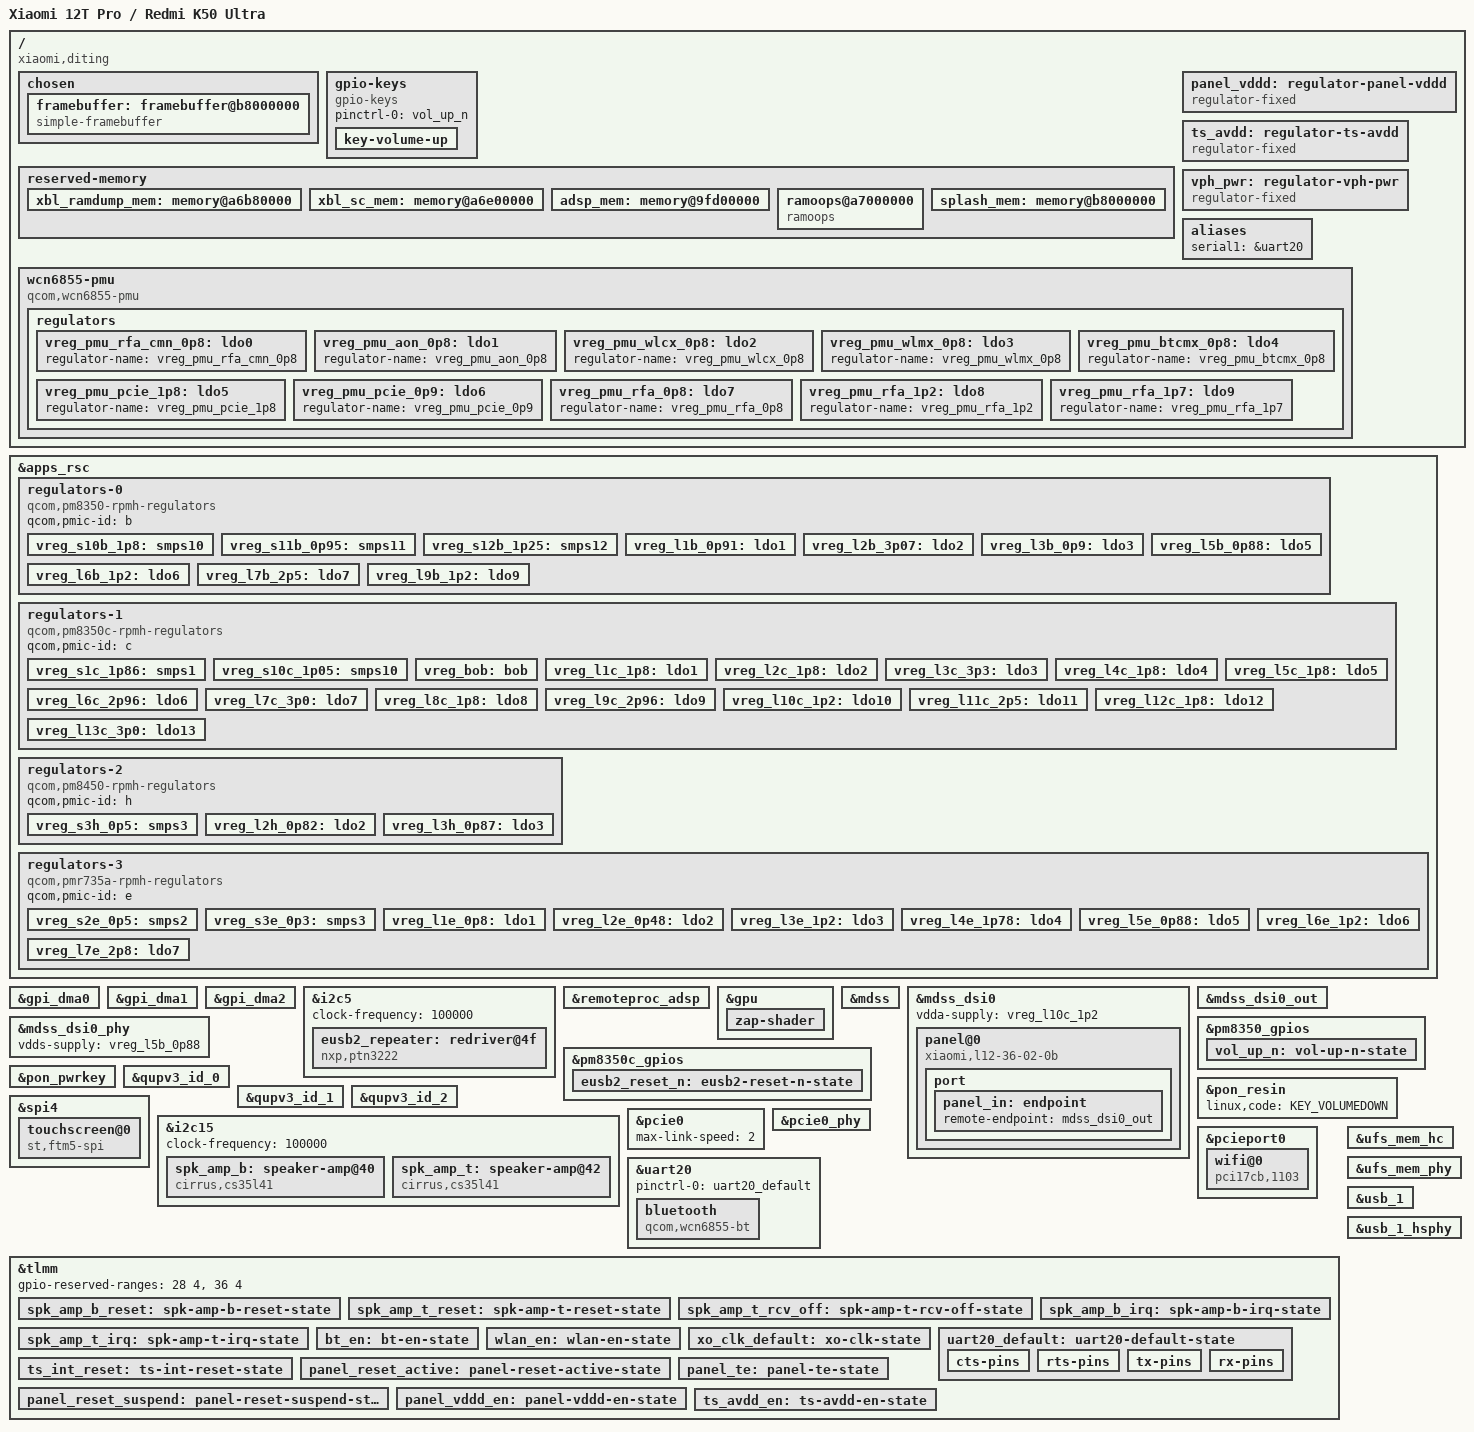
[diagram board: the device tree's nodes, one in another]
// SPDX-License-Identifier: BSD-3-Clause
/*
 * Xiaomi 12T Pro / Redmi K50 Ultra (diting)
 *
 * Local bring-up device tree. Board values were taken from the vendor
 * device tree of a 22081212UG (EEA, HyperOS OS3.0.5.0.VLFEUXM) unit, read
 * from /sys/firmware/fdt, and cross-checked with the sm8450-mainline
 * community sm8475-xiaomi-diting.dts by Jens Reidel.
 */

/dts-v1/;

#include <dt-bindings/gpio/gpio.h>
#include <dt-bindings/input/input.h>
#include <dt-bindings/interrupt-controller/irq.h>
#include <dt-bindings/pinctrl/qcom,pmic-gpio.h>
#include <dt-bindings/regulator/qcom,rpmh-regulator.h>

#include "sm8475.dtsi"
#include "pm8350.dtsi"
#include "pm8350b.dtsi"
#include "pm8350c.dtsi"
#include "pm8450.dtsi"
#include "pmk8350.dtsi"
#include "pmr735a.dtsi"

/*
 * The SM8450 reference carveouts below do not match this board: the vendor
 * DT places xbl_ramdump/xbl_sc and the ADSP elsewhere, and the generic
 * rmtfs location overlaps the Diting ADSP region. rmtfs is allocated
 * dynamically by the vendor kernel; it is left out until the modem is
 * brought up.
 */
/delete-node/ &adsp_mem;
/delete-node/ &rmtfs_mem;
/delete-node/ &xbl_ramdump_mem;
/delete-node/ &xbl_sc_mem;

/ {
	model = "Xiaomi 12T Pro / Redmi K50 Ultra";
	compatible = "xiaomi,diting", "qcom,sm8475";
	chassis-type = "handset";

	/*
	 * qcom,msm-id/qcom,board-id (needed by ABL to select a DTB from
	 * vendor_boot) are deprecated for this SoC generation and are added
	 * to a copy of the DTB by the boot image tooling instead.
	 */

	chosen {
		#address-cells = <2>;
		#size-cells = <2>;
		ranges;

		/* Continuous-splash buffer set up by ABL, 1220x2712 */
		framebuffer: framebuffer@b8000000 {
			compatible = "simple-framebuffer";
			reg = <0x0 0xb8000000 0x0 0x2b00000>;
			width = <1220>;
			height = <2712>;
			stride = <(1220 * 4)>;
			format = "a8r8g8b8";

			clocks = <&gcc GCC_DISP_HF_AXI_CLK>;
		};
	};

	gpio-keys {
		compatible = "gpio-keys";

		pinctrl-0 = <&vol_up_n>;
		pinctrl-names = "default";

		key-volume-up {
			label = "Volume Up";
			gpios = <&pm8350_gpios 6 GPIO_ACTIVE_LOW>;
			linux,code = <KEY_VOLUMEUP>;
			debounce-interval = <15>;
			linux,can-disable;
			wakeup-source;
		};
	};

	reserved-memory {
		xbl_ramdump_mem: memory@a6b80000 {
			reg = <0x0 0xa6b80000 0x0 0x280000>;
			no-map;
		};

		xbl_sc_mem: memory@a6e00000 {
			reg = <0x0 0xa6e00000 0x0 0x40000>;
			no-map;
		};

		adsp_mem: memory@9fd00000 {
			reg = <0x0 0x9fd00000 0x0 0x3100000>;
			no-map;
		};

		/*
		 * Same location and layout as the vendor ramoops (no dmesg
		 * records, 2 MiB console, 2 MiB pmsg), so a console log of a
		 * failed mainline boot can be read back from Android's
		 * /sys/fs/pstore after a warm reboot.
		 */
		ramoops@a7000000 {
			compatible = "ramoops";
			reg = <0x0 0xa7000000 0x0 0x400000>;
			console-size = <0x200000>;
			pmsg-size = <0x200000>;
		};

		splash_mem: memory@b8000000 {
			reg = <0x0 0xb8000000 0x0 0x2b00000>;
			no-map;
		};
	};

	/* Panel 1.2 V core supply, switched by TLMM 66 (vendor display_panel_vddd) */
	panel_vddd: regulator-panel-vddd {
		compatible = "regulator-fixed";
		regulator-name = "panel_vddd";
		regulator-min-microvolt = <1200000>;
		regulator-max-microvolt = <1200000>;
		gpio = <&tlmm 66 GPIO_ACTIVE_HIGH>;
		enable-active-high;
		regulator-boot-on;

		pinctrl-0 = <&panel_vddd_en>;
		pinctrl-names = "default";
	};

	/* Touchscreen analog supply, switched by TLMM 71 (vendor fts,avdd-gpio) */
	ts_avdd: regulator-ts-avdd {
		compatible = "regulator-fixed";
		regulator-name = "ts_avdd";
		gpio = <&tlmm 71 GPIO_ACTIVE_HIGH>;
		enable-active-high;
		startup-delay-us = <2000>;

		pinctrl-0 = <&ts_avdd_en>;
		pinctrl-names = "default";
	};

	vph_pwr: regulator-vph-pwr {
		compatible = "regulator-fixed";
		regulator-name = "vph_pwr";
		regulator-min-microvolt = <3700000>;
		regulator-max-microvolt = <3700000>;

		regulator-always-on;
		regulator-boot-on;
	};
};

&apps_rsc {
	/*
	 * Minimum voltages are the vendor boot-time (qcom,init-voltage) values,
	 * maxima the vendor DT constraints, so consumers that do not set a
	 * voltage run at the vendor voltage instead of the range minimum.
	 * Supply parents are not described yet (board power tree unverified).
	 */
	regulators-0 {
		compatible = "qcom,pm8350-rpmh-regulators";
		qcom,pmic-id = "b";

		vreg_s10b_1p8: smps10 {
			regulator-name = "vreg_s10b_1p8";
			regulator-min-microvolt = <1800000>;
			regulator-max-microvolt = <1800000>;
		};

		vreg_s11b_0p95: smps11 {
			regulator-name = "vreg_s11b_0p95";
			regulator-min-microvolt = <952000>;
			regulator-max-microvolt = <1170000>;
		};

		/* WLAN/BT rfa2: 1.35 V while the chip runs (vendor rfa2-config) */
		vreg_s12b_1p25: smps12 {
			regulator-name = "vreg_s12b_1p25";
			regulator-min-microvolt = <1350000>;
			regulator-max-microvolt = <2040000>;
		};

		vreg_l1b_0p91: ldo1 {
			regulator-name = "vreg_l1b_0p91";
			regulator-min-microvolt = <912000>;
			regulator-max-microvolt = <920000>;
			regulator-initial-mode = <RPMH_REGULATOR_MODE_HPM>;
		};

		vreg_l2b_3p07: ldo2 {
			regulator-name = "vreg_l2b_3p07";
			regulator-min-microvolt = <3072000>;
			regulator-max-microvolt = <3300000>;
			regulator-initial-mode = <RPMH_REGULATOR_MODE_HPM>;
		};

		vreg_l3b_0p9: ldo3 {
			regulator-name = "vreg_l3b_0p9";
			regulator-min-microvolt = <904000>;
			regulator-max-microvolt = <970000>;
			regulator-initial-mode = <RPMH_REGULATOR_MODE_HPM>;
		};

		vreg_l5b_0p88: ldo5 {
			regulator-name = "vreg_l5b_0p88";
			regulator-min-microvolt = <880000>;
			regulator-max-microvolt = <958000>;
			regulator-initial-mode = <RPMH_REGULATOR_MODE_HPM>;
		};

		vreg_l6b_1p2: ldo6 {
			regulator-name = "vreg_l6b_1p2";
			regulator-min-microvolt = <1200000>;
			regulator-max-microvolt = <1216000>;
			regulator-initial-mode = <RPMH_REGULATOR_MODE_HPM>;
		};

		vreg_l7b_2p5: ldo7 {
			regulator-name = "vreg_l7b_2p5";
			regulator-min-microvolt = <2504000>;
			regulator-max-microvolt = <3544000>;
			regulator-initial-mode = <RPMH_REGULATOR_MODE_HPM>;
		};

		vreg_l9b_1p2: ldo9 {
			regulator-name = "vreg_l9b_1p2";
			regulator-min-microvolt = <1200000>;
			regulator-max-microvolt = <1304000>;
			regulator-initial-mode = <RPMH_REGULATOR_MODE_HPM>;
		};
	};

	regulators-1 {
		compatible = "qcom,pm8350c-rpmh-regulators";
		qcom,pmic-id = "c";

		vreg_s1c_1p86: smps1 {
			regulator-name = "vreg_s1c_1p86";
			regulator-min-microvolt = <1880000>;
			regulator-max-microvolt = <2024000>;
		};

		vreg_s10c_1p05: smps10 {
			regulator-name = "vreg_s10c_1p05";
			regulator-min-microvolt = <1052000>;
			regulator-max-microvolt = <1170000>;
		};

		vreg_bob: bob {
			regulator-name = "vreg_bob";
			regulator-min-microvolt = <3008000>;
			regulator-max-microvolt = <3960000>;
			regulator-initial-mode = <RPMH_REGULATOR_MODE_AUTO>;
		};

		vreg_l1c_1p8: ldo1 {
			regulator-name = "vreg_l1c_1p8";
			regulator-min-microvolt = <1800000>;
			regulator-max-microvolt = <1800000>;
			regulator-initial-mode = <RPMH_REGULATOR_MODE_HPM>;
		};

		vreg_l2c_1p8: ldo2 {
			regulator-name = "vreg_l2c_1p8";
			regulator-min-microvolt = <1800000>;
			regulator-max-microvolt = <1980000>;
			regulator-initial-mode = <RPMH_REGULATOR_MODE_HPM>;
		};

		/*
		 * always-on and boot-on in the vendor DT, which asks for 3.3 V;
		 * this PLDO only has 3.296/3.304 V steps around it.
		 */
		vreg_l3c_3p3: ldo3 {
			regulator-name = "vreg_l3c_3p3";
			regulator-min-microvolt = <3296000>;
			regulator-max-microvolt = <3304000>;
			regulator-initial-mode = <RPMH_REGULATOR_MODE_HPM>;
			regulator-boot-on;
			regulator-always-on;
		};

		vreg_l4c_1p8: ldo4 {
			regulator-name = "vreg_l4c_1p8";
			regulator-min-microvolt = <1620000>;
			regulator-max-microvolt = <3300000>;
			regulator-initial-mode = <RPMH_REGULATOR_MODE_HPM>;
		};

		vreg_l5c_1p8: ldo5 {
			regulator-name = "vreg_l5c_1p8";
			regulator-min-microvolt = <1620000>;
			regulator-max-microvolt = <3300000>;
			regulator-initial-mode = <RPMH_REGULATOR_MODE_HPM>;
		};

		vreg_l6c_2p96: ldo6 {
			regulator-name = "vreg_l6c_2p96";
			regulator-min-microvolt = <2960000>;
			regulator-max-microvolt = <3544000>;
			regulator-initial-mode = <RPMH_REGULATOR_MODE_HPM>;
		};

		vreg_l7c_3p0: ldo7 {
			regulator-name = "vreg_l7c_3p0";
			regulator-min-microvolt = <3000000>;
			regulator-max-microvolt = <3544000>;
			regulator-initial-mode = <RPMH_REGULATOR_MODE_HPM>;
		};

		vreg_l8c_1p8: ldo8 {
			regulator-name = "vreg_l8c_1p8";
			regulator-min-microvolt = <1800000>;
			regulator-max-microvolt = <2000000>;
			regulator-initial-mode = <RPMH_REGULATOR_MODE_HPM>;
		};

		vreg_l9c_2p96: ldo9 {
			regulator-name = "vreg_l9c_2p96";
			regulator-min-microvolt = <2960000>;
			regulator-max-microvolt = <3544000>;
			regulator-initial-mode = <RPMH_REGULATOR_MODE_HPM>;
		};

		vreg_l10c_1p2: ldo10 {
			regulator-name = "vreg_l10c_1p2";
			regulator-min-microvolt = <1200000>;
			regulator-max-microvolt = <1304000>;
			regulator-initial-mode = <RPMH_REGULATOR_MODE_HPM>;
		};

		vreg_l11c_2p5: ldo11 {
			regulator-name = "vreg_l11c_2p5";
			regulator-min-microvolt = <2504000>;
			regulator-max-microvolt = <3008000>;
			regulator-initial-mode = <RPMH_REGULATOR_MODE_HPM>;
		};

		vreg_l12c_1p8: ldo12 {
			regulator-name = "vreg_l12c_1p8";
			regulator-min-microvolt = <1800000>;
			regulator-max-microvolt = <1980000>;
			regulator-initial-mode = <RPMH_REGULATOR_MODE_HPM>;
		};

		/* Panel vci: vendor dsi_panel_pwr_supply_L12 asks for 3.0 V */
		vreg_l13c_3p0: ldo13 {
			regulator-name = "vreg_l13c_3p0";
			regulator-min-microvolt = <3000000>;
			regulator-max-microvolt = <3000000>;
			regulator-initial-mode = <RPMH_REGULATOR_MODE_HPM>;
		};
	};

	regulators-2 {
		compatible = "qcom,pm8450-rpmh-regulators";
		qcom,pmic-id = "h";

		vreg_s3h_0p5: smps3 {
			regulator-name = "vreg_s3h_0p5";
			regulator-min-microvolt = <504000>;
			regulator-max-microvolt = <570000>;
		};

		vreg_l2h_0p82: ldo2 {
			regulator-name = "vreg_l2h_0p82";
			regulator-min-microvolt = <820000>;
			regulator-max-microvolt = <958000>;
			regulator-initial-mode = <RPMH_REGULATOR_MODE_HPM>;
		};

		vreg_l3h_0p87: ldo3 {
			regulator-name = "vreg_l3h_0p87";
			regulator-min-microvolt = <866000>;
			regulator-max-microvolt = <958000>;
			regulator-initial-mode = <RPMH_REGULATOR_MODE_HPM>;
		};

		/* ldo4: listed in the vendor DT, but absent from this unit's cmd-db */
	};

	regulators-3 {
		compatible = "qcom,pmr735a-rpmh-regulators";
		qcom,pmic-id = "e";

		/* WLAN aon / WCN6855 PMU MX: vendor cnss votes 1.012 V */
		vreg_s2e_0p5: smps2 {
			regulator-name = "vreg_s2e_0p5";
			regulator-min-microvolt = <1012000>;
			regulator-max-microvolt = <1040000>;
		};

		vreg_s3e_0p3: smps3 {
			regulator-name = "vreg_s3e_0p3";
			regulator-min-microvolt = <300000>;
			regulator-max-microvolt = <2352000>;
		};

		vreg_l1e_0p8: ldo1 {
			regulator-name = "vreg_l1e_0p8";
			regulator-min-microvolt = <800000>;
			regulator-max-microvolt = <880000>;
			regulator-initial-mode = <RPMH_REGULATOR_MODE_HPM>;
		};

		vreg_l2e_0p48: ldo2 {
			regulator-name = "vreg_l2e_0p48";
			regulator-min-microvolt = <480000>;
			regulator-max-microvolt = <1200000>;
			regulator-initial-mode = <RPMH_REGULATOR_MODE_HPM>;
		};

		vreg_l3e_1p2: ldo3 {
			regulator-name = "vreg_l3e_1p2";
			regulator-min-microvolt = <1200000>;
			regulator-max-microvolt = <1200000>;
			regulator-initial-mode = <RPMH_REGULATOR_MODE_HPM>;
		};

		vreg_l4e_1p78: ldo4 {
			regulator-name = "vreg_l4e_1p78";
			regulator-min-microvolt = <1776000>;
			regulator-max-microvolt = <1776000>;
			regulator-initial-mode = <RPMH_REGULATOR_MODE_HPM>;
		};

		vreg_l5e_0p88: ldo5 {
			regulator-name = "vreg_l5e_0p88";
			regulator-min-microvolt = <880000>;
			regulator-max-microvolt = <920000>;
			regulator-initial-mode = <RPMH_REGULATOR_MODE_HPM>;
		};

		vreg_l6e_1p2: ldo6 {
			regulator-name = "vreg_l6e_1p2";
			regulator-min-microvolt = <1200000>;
			regulator-max-microvolt = <1200000>;
			regulator-initial-mode = <RPMH_REGULATOR_MODE_HPM>;
		};

		/* WLAN/BT antenna switch (vendor vdd-wlan-ant-share / bt-vdd-asd) */
		vreg_l7e_2p8: ldo7 {
			regulator-name = "vreg_l7e_2p8";
			regulator-min-microvolt = <2800000>;
			regulator-max-microvolt = <2800000>;
			regulator-always-on;
		};
	};
};

&gpi_dma0 {
	status = "okay";
};

&gpi_dma1 {
	status = "okay";
};

&gpi_dma2 {
	status = "okay";
};

&i2c5 {
	clock-frequency = <100000>;
	status = "okay";

	/* fsa4480 typec mux @ 0x42 and wl2866d camera PMIC @ 0x28: TODO */

	/*
	 * The vendor DT uses a generic "nxp,eusb2-repeater" compatible at
	 * 0x4f; the PTN3222 is NXP's eUSB2 repeater at this address.
	 * INFERRED, not confirmed by reading a chip id.
	 */
	eusb2_repeater: redriver@4f {
		compatible = "nxp,ptn3222";
		reg = <0x4f>;
		#phy-cells = <0>;

		vdd3v3-supply = <&vreg_l2b_3p07>;
		vdd1v8-supply = <&vreg_s10b_1p8>;

		reset-gpios = <&pm8350c_gpios 7 GPIO_ACTIVE_LOW>;

		pinctrl-0 = <&eusb2_reset_n>;
		pinctrl-names = "default";
	};
};

&remoteproc_adsp {
	/* squashed from the vendor firmware_mnt adsp.mdt + adsp.bNN */
	firmware-name = "qcom/sm8475/xiaomi/diting/adsp.mbn";
	status = "okay";
};

&gpu {
	status = "okay";

	zap-shader {
		firmware-name = "qcom/sm8475/xiaomi/diting/a730_zap.mbn";
	};
};

&mdss {
	status = "okay";
};

&mdss_dsi0 {
	vdda-supply = <&vreg_l10c_1p2>;
	status = "okay";

	panel@0 {
		compatible = "xiaomi,l12-36-02-0b";
		reg = <0>;

		reset-gpios = <&tlmm 0 GPIO_ACTIVE_LOW>;

		vddio-supply = <&vreg_l12c_1p8>;
		vddd-supply = <&panel_vddd>;
		vci-supply = <&vreg_l13c_3p0>;

		pinctrl-0 = <&panel_reset_active>, <&panel_te>;
		pinctrl-1 = <&panel_reset_suspend>, <&panel_te>;
		pinctrl-names = "default", "sleep";

		port {
			panel_in: endpoint {
				remote-endpoint = <&mdss_dsi0_out>;
			};
		};
	};
};

&mdss_dsi0_out {
	data-lanes = <0 1 2 3>;
	remote-endpoint = <&panel_in>;
};

&mdss_dsi0_phy {
	vdds-supply = <&vreg_l5b_0p88>;
	status = "okay";
};

&pm8350_gpios {
	vol_up_n: vol-up-n-state {
		pins = "gpio6";
		function = PMIC_GPIO_FUNC_NORMAL;
		power-source = <1>;
		bias-pull-up;
		input-enable;
	};
};

&pm8350c_gpios {
	eusb2_reset_n: eusb2-reset-n-state {
		pins = "gpio7";
		function = PMIC_GPIO_FUNC_NORMAL;
		power-source = <1>;
		qcom,drive-strength = <PMIC_GPIO_STRENGTH_MED>;
		bias-disable;
		output-enable;
	};
};

&pon_pwrkey {
	status = "okay";
};

&pon_resin {
	linux,code = <KEY_VOLUMEDOWN>;
	status = "okay";
};

&qupv3_id_0 {
	status = "okay";
};

&qupv3_id_1 {
	status = "okay";
};

&qupv3_id_2 {
	status = "okay";
};

&spi4 {
	status = "okay";

	touchscreen@0 {
		compatible = "st,ftm5-spi";
		reg = <0>;
		spi-max-frequency = <12000000>;

		interrupts-extended = <&tlmm 21 IRQ_TYPE_LEVEL_LOW>;
		reset-gpios = <&tlmm 20 GPIO_ACTIVE_LOW>;

		vdd-supply = <&vreg_l2c_1p8>;
		avdd-supply = <&ts_avdd>;

		/* 10x the panel resolution ("super resolution" firmware) */
		touchscreen-size-x = <12200>;
		touchscreen-size-y = <27120>;

		pinctrl-0 = <&ts_int_reset>;
		pinctrl-names = "default";
	};
};

/* Loudspeaker amplifiers: Android I2C bus 2 = QUP SE15 */
&i2c15 {
	clock-frequency = <100000>;
	status = "okay";

	/* vendor cs35l41@40 */
	spk_amp_b: speaker-amp@40 {
		compatible = "cirrus,cs35l41";
		reg = <0x40>;
		interrupts-extended = <&tlmm 63 IRQ_TYPE_LEVEL_LOW>;
		reset-gpios = <&tlmm 3 GPIO_ACTIVE_HIGH>;
		pinctrl-0 = <&spk_amp_b_reset>, <&spk_amp_b_irq>;
		pinctrl-names = "default";
		cirrus,boost-type = <0>;
		cirrus,boost-peak-milliamp = <4000>;
		cirrus,boost-ind-nanohenry = <1000>;
		cirrus,boost-cap-microfarad = <15>;
		cirrus,asp-sdout-hiz = <3>;
		cirrus,gpio2-src-select = <4>;
		cirrus,gpio2-output-enable;
		cirrus,subsystem-id = "diting";
		sound-name-prefix = "B";
		#sound-dai-cells = <1>;
	};

	/* vendor cs35l41@42 */
	spk_amp_t: speaker-amp@42 {
		compatible = "cirrus,cs35l41";
		reg = <0x42>;
		interrupts-extended = <&tlmm 88 IRQ_TYPE_LEVEL_LOW>;
		reset-gpios = <&tlmm 1 GPIO_ACTIVE_HIGH>;
		pinctrl-0 = <&spk_amp_t_reset>, <&spk_amp_t_irq>, <&spk_amp_t_rcv_off>;
		pinctrl-names = "default";
		cirrus,boost-type = <0>;
		cirrus,boost-peak-milliamp = <4000>;
		cirrus,boost-ind-nanohenry = <1000>;
		cirrus,boost-cap-microfarad = <15>;
		cirrus,asp-sdout-hiz = <3>;
		cirrus,gpio2-src-select = <4>;
		cirrus,gpio2-output-enable;
		cirrus,subsystem-id = "diting";
		sound-name-prefix = "T";
		#sound-dai-cells = <1>;
	};
};

&pcie0 {
	max-link-speed = <2>;
	status = "okay";
};

/* vendor pcie0 vreg-0p9 = pm8350 L5, vreg-1p8 = pm8350c L10 at 1.2 V */
&pcie0_phy {
	vdda-phy-supply = <&vreg_l5b_0p88>;
	vdda-pll-supply = <&vreg_l10c_1p2>;
	status = "okay";
};

/* QCA6490 (WCN6855 family), PCI ID 17cb:1103 on the vendor kernel */
&pcieport0 {
	wifi@0 {
		compatible = "pci17cb,1103";
		reg = <0x10000 0x0 0x0 0x0 0x0>;

		vddrfacmn-supply = <&vreg_pmu_rfa_cmn_0p8>;
		vddaon-supply = <&vreg_pmu_aon_0p8>;
		vddwlcx-supply = <&vreg_pmu_wlcx_0p8>;
		vddwlmx-supply = <&vreg_pmu_wlmx_0p8>;
		vddpcie1p8-supply = <&vreg_pmu_pcie_1p8>;
		vddpcie0p9-supply = <&vreg_pmu_pcie_0p9>;
		vddrfa0p8-supply = <&vreg_pmu_rfa_0p8>;
		vddrfa1p2-supply = <&vreg_pmu_rfa_1p2>;
		vddrfa1p8-supply = <&vreg_pmu_rfa_1p7>;
	};
};

/* Bluetooth UART: vendor qcom,qup_uart@894000 */
&uart20 {
	pinctrl-0 = <&uart20_default>;
	pinctrl-names = "default";
	status = "okay";

	bluetooth {
		compatible = "qcom,wcn6855-bt";

		vddrfacmn-supply = <&vreg_pmu_rfa_cmn_0p8>;
		vddaon-supply = <&vreg_pmu_aon_0p8>;
		vddwlcx-supply = <&vreg_pmu_wlcx_0p8>;
		vddwlmx-supply = <&vreg_pmu_wlmx_0p8>;
		vddbtcmx-supply = <&vreg_pmu_btcmx_0p8>;
		vddrfa0p8-supply = <&vreg_pmu_rfa_0p8>;
		vddrfa1p2-supply = <&vreg_pmu_rfa_1p2>;
		vddrfa1p7-supply = <&vreg_pmu_rfa_1p7>;

		/* vendor bt_firmware partition, packaged locally */
		firmware-name = "diting/hpnv21", "diting/hpbtfw21.tlv";
	};
};

&tlmm {
	/* Secure-world owned, per qcom,gpios-reserved in the vendor DT */
	gpio-reserved-ranges = <28 4>, <36 4>;

	spk_amp_b_reset: spk-amp-b-reset-state {
		pins = "gpio3";
		function = "gpio";
		drive-strength = <16>;
		bias-disable;
	};

	spk_amp_t_reset: spk-amp-t-reset-state {
		pins = "gpio1";
		function = "gpio";
		drive-strength = <16>;
		bias-disable;
	};

	/*
	 * The top amplifier also drives the earpiece through a switch on
	 * gpio52 (vendor spk-sw-gpios); low selects the loudspeaker, as Android
	 * does for media playback ("Spksw Gpio Switch" Off).
	 */
	spk_amp_t_rcv_off: spk-amp-t-rcv-off-state {
		pins = "gpio52";
		function = "gpio";
		drive-strength = <2>;
		bias-disable;
		output-low;
	};

	spk_amp_b_irq: spk-amp-b-irq-state {
		pins = "gpio63";
		function = "gpio";
		drive-strength = <2>;
		bias-pull-up;
	};

	spk_amp_t_irq: spk-amp-t-irq-state {
		pins = "gpio88";
		function = "gpio";
		drive-strength = <2>;
		bias-pull-up;
	};

	bt_en: bt-en-state {
		pins = "gpio81";
		function = "gpio";
		drive-strength = <16>;
		output-low;
		bias-pull-down;
	};

	wlan_en: wlan-en-state {
		pins = "gpio80";
		function = "gpio";
		drive-strength = <16>;
		output-low;
		bias-pull-down;
	};

	xo_clk_default: xo-clk-state {
		pins = "gpio204";
		function = "gpio";
		drive-strength = <16>;
		output-low;
		bias-pull-down;
	};

	uart20_default: uart20-default-state {
		cts-pins {
			pins = "gpio76";
			function = "qup20";
			drive-strength = <2>;
			bias-disable;
		};

		rts-pins {
			pins = "gpio77";
			function = "qup20";
			drive-strength = <2>;
			bias-pull-down;
		};

		tx-pins {
			pins = "gpio78";
			function = "qup20";
			drive-strength = <2>;
			bias-pull-up;
		};

		rx-pins {
			pins = "gpio79";
			function = "qup20";
			drive-strength = <2>;
			bias-disable;
		};
	};

	ts_int_reset: ts-int-reset-state {
		pins = "gpio20", "gpio21";
		function = "gpio";
		drive-strength = <8>;
		bias-pull-up;
	};

	panel_reset_active: panel-reset-active-state {
		pins = "gpio0";
		function = "gpio";
		drive-strength = <8>;
		bias-disable;
	};

	panel_reset_suspend: panel-reset-suspend-state {
		pins = "gpio0";
		function = "gpio";
		drive-strength = <2>;
		bias-pull-down;
	};

	panel_te: panel-te-state {
		pins = "gpio86";
		function = "mdp_vsync";
		drive-strength = <2>;
		bias-pull-down;
	};

	panel_vddd_en: panel-vddd-en-state {
		pins = "gpio66";
		function = "gpio";
		drive-strength = <2>;
		bias-disable;
	};

	ts_avdd_en: ts-avdd-en-state {
		pins = "gpio71";
		function = "gpio";
		drive-strength = <2>;
		bias-disable;
	};
};

&ufs_mem_hc {
	reset-gpios = <&tlmm 210 GPIO_ACTIVE_LOW>;

	vcc-supply = <&vreg_l7b_2p5>;
	vcc-max-microamp = <1100000>;
	vccq-supply = <&vreg_l9b_1p2>;
	vccq-max-microamp = <1200000>;

	status = "okay";
};

&ufs_mem_phy {
	vdda-phy-supply = <&vreg_l5b_0p88>;
	vdda-pll-supply = <&vreg_l10c_1p2>;

	status = "okay";
};

&usb_1 {
	/* Only the eUSB2 path is wired up so far; no USB3/DP, no role switch */
	dr_mode = "peripheral";
	maximum-speed = "high-speed";
	qcom,select-utmi-as-pipe-clk;

	phys = <&usb_1_hsphy>;
	phy-names = "usb2-phy";

	status = "okay";
};

&usb_1_hsphy {
	vdd-supply = <&vreg_l5b_0p88>;
	vdda12-supply = <&vreg_l10c_1p2>;

	phys = <&eusb2_repeater>;

	status = "okay";
};

/ {
	aliases {
		serial1 = &uart20;	/* qcom_geni_serial needs a line number */
	};

	/* WLAN_EN 80, BT_EN 81, SW_CTRL 82, XO_CLK 204: vendor cnss/bt nodes */
	wcn6855-pmu {
		compatible = "qcom,wcn6855-pmu";

		pinctrl-0 = <&bt_en>, <&wlan_en>, <&xo_clk_default>;
		pinctrl-names = "default";

		wlan-enable-gpios = <&tlmm 80 GPIO_ACTIVE_HIGH>;
		bt-enable-gpios = <&tlmm 81 GPIO_ACTIVE_HIGH>;
		swctrl-gpios = <&tlmm 82 GPIO_ACTIVE_HIGH>;
		xo-clk-gpios = <&tlmm 204 GPIO_ACTIVE_HIGH>;

		vddio-supply = <&vreg_s10b_1p8>;
		vddaon-supply = <&vreg_s11b_0p95>;
		vddpmu-supply = <&vreg_s12b_1p25>;
		vddpmumx-supply = <&vreg_s2e_0p5>;
		vddpmucx-supply = <&vreg_s11b_0p95>;
		vddrfa0p95-supply = <&vreg_s11b_0p95>;
		vddrfa1p3-supply = <&vreg_s12b_1p25>;
		vddrfa1p9-supply = <&vreg_s1c_1p86>;
		vddpcie1p3-supply = <&vreg_s12b_1p25>;
		vddpcie1p9-supply = <&vreg_s1c_1p86>;

		regulators {
			vreg_pmu_rfa_cmn_0p8: ldo0 {
				regulator-name = "vreg_pmu_rfa_cmn_0p8";
			};

			vreg_pmu_aon_0p8: ldo1 {
				regulator-name = "vreg_pmu_aon_0p8";
			};

			vreg_pmu_wlcx_0p8: ldo2 {
				regulator-name = "vreg_pmu_wlcx_0p8";
			};

			vreg_pmu_wlmx_0p8: ldo3 {
				regulator-name = "vreg_pmu_wlmx_0p8";
			};

			vreg_pmu_btcmx_0p8: ldo4 {
				regulator-name = "vreg_pmu_btcmx_0p8";
			};

			vreg_pmu_pcie_1p8: ldo5 {
				regulator-name = "vreg_pmu_pcie_1p8";
			};

			vreg_pmu_pcie_0p9: ldo6 {
				regulator-name = "vreg_pmu_pcie_0p9";
			};

			vreg_pmu_rfa_0p8: ldo7 {
				regulator-name = "vreg_pmu_rfa_0p8";
			};

			vreg_pmu_rfa_1p2: ldo8 {
				regulator-name = "vreg_pmu_rfa_1p2";
			};

			vreg_pmu_rfa_1p7: ldo9 {
				regulator-name = "vreg_pmu_rfa_1p7";
			};
		};
	};
};
